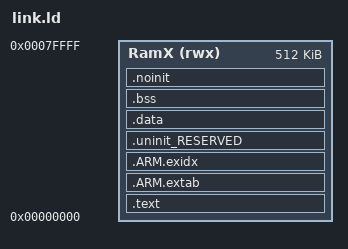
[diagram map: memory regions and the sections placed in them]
MEMORY
{
  RamX (rwx) : ORIGIN = 0x0, LENGTH = 0x80000 /* 256K*2 bytes */
}

ENTRY(_init_internal)

SECTIONS
{
    /* MAIN TEXT SECTION */
    .text : ALIGN(4)
    {
        FILL(0xff)
        __vectors_start__ = ABSOLUTE(.) ;
        KEEP(*(.bin_header))
        *(.imports);
        LONG(0);

        /* Global Section Table */
        . = ALIGN(4) ;
        __section_table_start = .;
        __data_section_table = .;
        LONG(LOADADDR(.data));
        LONG(    ADDR(.data));
        LONG(  SIZEOF(.data));
        __data_section_table_end = .;
        __bss_section_table = .;
        LONG(    ADDR(.bss));
        LONG(  SIZEOF(.bss));
        __bss_section_table_end = .;
        __section_table_end = . ;
        /* End of Global Section Table */

        *(.after_vectors*)

        *(.text*)
        *(.rodata .rodata.*)
        *(__global_locale)
        . = ALIGN(4);

        /* C++ constructors etc */
        . = ALIGN(4);
        KEEP(*(.init))

        . = ALIGN(4);
        __preinit_array_start = .;
        KEEP (*(.preinit_array))
        __preinit_array_end = .;

        . = ALIGN(4);
        __init_array_start = .;
        KEEP (*(SORT(.init_array.*)))
        KEEP (*(.init_array))
        __init_array_end = .;

        KEEP(*(.fini));

        . = ALIGN(0x4);
        KEEP (*crtbegin.o(.ctors))
        KEEP (*(EXCLUDE_FILE (*crtend.o) .ctors))
        KEEP (*(SORT(.ctors.*)))
        KEEP (*crtend.o(.ctors))

        . = ALIGN(0x4);
        KEEP (*crtbegin.o(.dtors))
        KEEP (*(EXCLUDE_FILE (*crtend.o) .dtors))
        KEEP (*(SORT(.dtors.*)))
        KEEP (*crtend.o(.dtors))
    } > RamX

    /*
     * for exception handling/unwind - some Newlib functions (in common
     * with C++ and STDC++) use this.
     */
    .ARM.extab : ALIGN(4)
    {
    	*(.ARM.extab* .gnu.linkonce.armextab.*)
    } > RamX
    __exidx_start = .;

    .ARM.exidx : ALIGN(4)
    {
    	*(.ARM.exidx* .gnu.linkonce.armexidx.*)
    } > RamX
    __exidx_end = .;

    _etext = .;
    
    .uninit_RESERVED : ALIGN(4)
    {
        KEEP(*(.bss.$RESERVED*))
        . = ALIGN(4) ;
        _end_uninit_RESERVED = .;
    } > RamX

    /* Main DATA section (Ram0_32) */
    .data : ALIGN(4)
    {
       FILL(0xff)
       _data = . ;
       *(vtable)
       *(.ramfunc*)
       *(.data*)
       . = ALIGN(4) ;
       _edata = . ;
    } > RamX

    /* MAIN BSS SECTION */
    .bss : ALIGN(4)
    {
        _bss = .;
        *(.bss*)
        *(COMMON)
        . = ALIGN(4) ;
        _ebss = .;
        PROVIDE(end = .);
        __end__ = .;
    } > RamX

    /* DEFAULT NOINIT SECTION */
    .noinit (NOLOAD): ALIGN(4)
    {
        _noinit = .;
        *(.noinit*)
         . = ALIGN(4) ;
        _end_noinit = .;
    } > RamX

    PROVIDE(_pvHeapStart = .);
}
